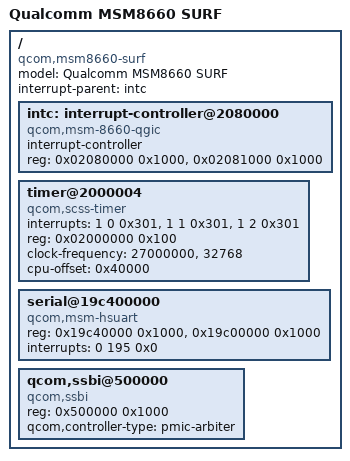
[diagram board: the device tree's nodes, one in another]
/dts-v1/;

/include/ "skeleton.dtsi"

/ {
	model = "Qualcomm MSM8660 SURF";
	compatible = "qcom,msm8660-surf", "qcom,msm8660";
	interrupt-parent = <&intc>;

	intc: interrupt-controller@2080000 {
		compatible = "qcom,msm-8660-qgic";
		interrupt-controller;
		#interrupt-cells = <3>;
		reg = < 0x02080000 0x1000 >,
		      < 0x02081000 0x1000 >;
	};

	timer@2000004 {
		compatible = "qcom,scss-timer", "qcom,msm-timer";
		interrupts = <1 0 0x301>,
			     <1 1 0x301>,
			     <1 2 0x301>;
		reg = <0x02000000 0x100>;
		clock-frequency = <27000000>,
				  <32768>;
		cpu-offset = <0x40000>;
	};

	serial@19c400000 {
		compatible = "qcom,msm-hsuart", "qcom,msm-uart";
		reg = <0x19c40000 0x1000>,
		      <0x19c00000 0x1000>;
		interrupts = <0 195 0x0>;
	};

	qcom,ssbi@500000 {
		compatible = "qcom,ssbi";
		reg = <0x500000 0x1000>;
		qcom,controller-type = "pmic-arbiter";
	};
};
